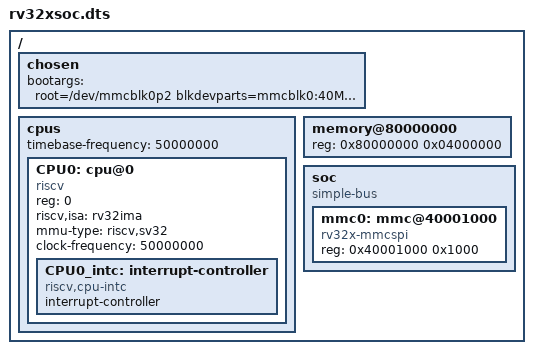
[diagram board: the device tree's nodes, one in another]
/dts-v1/;

/ {
	#address-cells = <1>;
	#size-cells = <1>;
	//compatible = "ck,rv32xsoc";
	//model = "ck,rv32xsoc";

	chosen {
		bootargs ="root=/dev/mmcblk0p2 blkdevparts=mmcblk0:40M(kernel),60M(root) console=hvc earlycon=sbi mmc_core.use_spi_crc=0";
	};
	cpus {
		#address-cells = <1>;
		#size-cells = <0>;
		timebase-frequency = <50000000>;
		CPU0:cpu@0 {
			device_type = "cpu";
			reg = <0>;
			status = "okay";
			compatible = "riscv";
			riscv,isa = "rv32ima";
			mmu-type = "riscv,sv32";
			clock-frequency = <50000000>;
			CPU0_intc: interrupt-controller {
				#interrupt-cells = <1>;
				interrupt-controller;
				compatible = "riscv,cpu-intc";
			};
		};
	};
	memory@80000000 {
		device_type = "memory";
		reg = <0x80000000 0x04000000>;
	};

	soc {
		#address-cells = <1>;
		#size-cells = <1>;
		compatible = "simple-bus";
		ranges;

		mmc0: mmc@40001000 {
			compatible = "rv32x-mmcspi";
			reg = <0x40001000 0x1000>;
		};
	};
};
